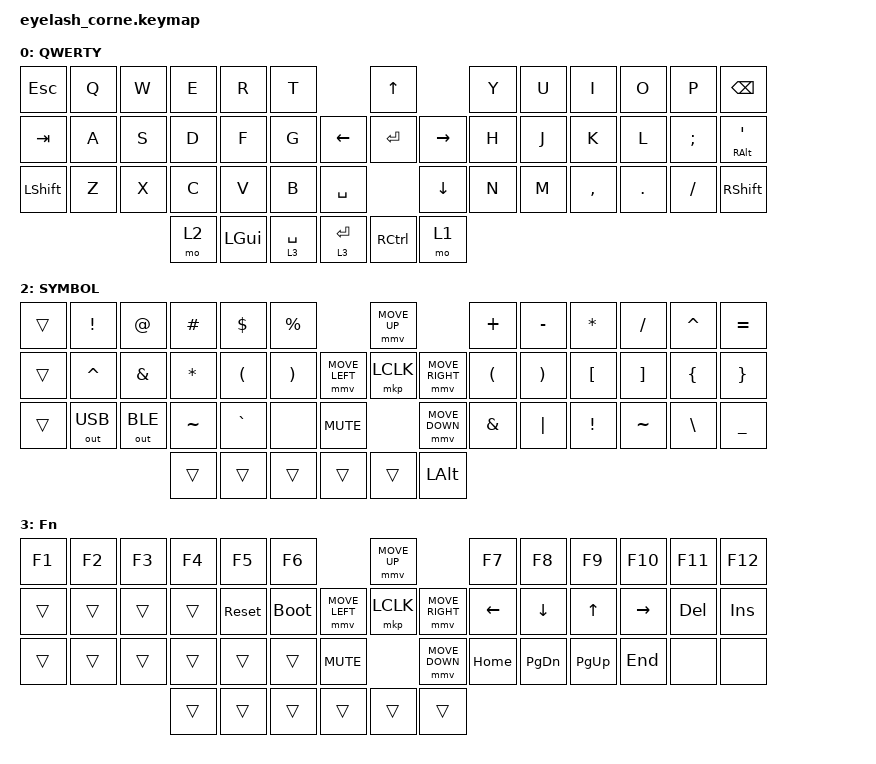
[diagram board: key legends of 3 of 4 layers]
#define ZMK_POINTING_DEFAULT_MOVE_VAL 1200  // 600
#define ZMK_POINTING_DEFAULT_SCRL_VAL 25   // 10

#include <input/processors.dtsi>
#include <zephyr/dt-bindings/input/input-event-codes.h>
#include <behaviors.dtsi>
#include <dt-bindings/zmk/bt.h>
#include <dt-bindings/zmk/ext_power.h>
#include <dt-bindings/zmk/keys.h>
#include <dt-bindings/zmk/outputs.h>
#include <dt-bindings/zmk/pointing.h>
#include <dt-bindings/zmk/rgb.h>

&mmv_input_listener { input-processors = <&zip_xy_scaler 2 1>; };

&msc_input_listener { input-processors = <&zip_scroll_scaler 2 1>; };

&msc {
    acceleration-exponent = <1>;      // 0
    time-to-max-speed-ms = <100>;       // 300
    delay-ms = <0>;                   // 0
};

&mmv {
    time-to-max-speed-ms = <500>;
    acceleration-exponent = <1>;
    trigger-period-ms = <16>;
};

/ {
    behaviors {
        td0: td0 {
            compatible = "zmk,behavior-tap-dance";
            display-name = "Shift/Caps Lock Tap Dance";
            #binding-cells = <0>;
            bindings = <&kp LEFT_SHIFT>, <&kp CAPS>;
        };
    };

    rgb_encoder: rgb_encoder {
        compatible = "zmk,behavior-sensor-rotate";
        #sensor-binding-cells = <0>;
        bindings = <&rgb_ug RGB_BRI>, <&rgb_ug RGB_BRD>;
    };

    scroll_encoder: scroll_encoder {
        compatible = "zmk,behavior-sensor-rotate";
        #sensor-binding-cells = <0>;
        bindings = <&msc SCRL_DOWN>, <&msc SCRL_UP>;
        tap-ms = <100>;
    };

    keymap {
        compatible = "zmk,keymap";

        default_layer {
            display-name = "QWERTY";

            // --------------------------------------------------------------------------------
            // | ESC |  Q  |  W  |  E  |  R  |  T  |   |  Y  |  U  |  I  |  O  |  P  | BKSP |
            // | TAB |  A  |  S  |  D  |  F  |  G  |   |  H  |  J  |  K  |  L  |  ;  |'/ALT | 
            // | SHFT|  Z  |  X  |  C  |  V  |  B  |   |  N  |  M  |  ,  |  .  |  /  | SHFT |
            //                   | SYM | CMD | SPC |   | ENT | CTRL| NUM |

            bindings = <
&kp ESC    &kp Q  &kp W  &kp E   &kp R     &kp T                     &kp UP                 &kp Y        &kp U      &kp I      &kp O    &kp P     &kp BSPC
&kp TAB    &kp A  &kp S  &kp D   &kp F     &kp G        &kp LEFT    &kp ENTER  &kp RIGHT    &kp H        &kp J      &kp K      &kp L    &kp SEMI  &mt RALT SQT
&kp LSHFT  &kp Z  &kp X  &kp C   &kp V     &kp B    &kp SPACE        &kp DOWN               &kp N        &kp M      &kp COMMA  &kp DOT  &kp FSLH  &kp RSHFT
                         &mo 2  &kp LGUI  &lt 3 SPACE     &lt 3 ENTER  &kp RCTRL  &mo 1  
            >;
            sensor-bindings = <&inc_dec_kp C_VOLUME_UP C_VOLUME_DOWN>;
        };

        lower_layer {
            display-name = "NUMBER";

            // -----------------------------------------------------------------------------------------
            // | ESC  |  1  |  2  |  3  |  4  |  5  |    | BT1 | BT2 | BT3 | BT4 |BT_CLR| BKSP |
            // | TAB  |  6  |  7  |  8  |  9  |  0  |    | LFT | DWN | UP  | RGT | HOME | PGUP |
            // | SHFT |L_OFF|L_ON |     |     |     |    | INS | DEL |     |     | END  | PGDN |
            //                    | SYM | CMD | SPC |    | ENT | CTRL| NUM |

            bindings = <
&trans   &kp N1           &kp N2          &kp N3    &kp N4    &kp N5               &mmv MOVE_UP     &bt BT_SEL 0       &bt BT_SEL 1  &bt BT_SEL 2   &bt BT_SEL 3   &bt BT_CLR_ALL  &kp BSPC
&trans   &kp N6           &kp N7          &kp N8    &kp N9    &kp N0   &mmv MOVE_LEFT  &mkp LCLK      &mmv MOVE_RIGHT  &kp LEFT    &kp LEFT       &kp DOWN      &kp UP         &kp RIGHT      &kp HOME        &kp PG_UP     
&trans   &rgb_ug RGB_OFF  &rgb_ug RGB_ON  &none     &none     &none    &kp C_MUTE      &mmv MOVE_DOWN                  &kp INS        &kp DEL       &none          &none          &kp END         &kp PG_DN
                          &trans          &trans    &trans    &trans        &trans         &trans
            >;
            sensor-bindings = <&scroll_encoder>;
        };
//&ext_power EP_OFF  &ext_power EP_ON  &rgb_ug RGB_EFF    &rgb_ug RGB_EFR  &rgb_ug RGB_SPI  &rgb_ug RGB_BRI  &rgb_ug RGB_BRD  
        raise_layer {
            display-name = "SYMBOL";

            // -----------------------------------------------------------------------------------------
            // | ESC |  !  |  @  |  #  |  $  |  %  |   |  +  |  -  |  *  |  /  | ^  |  =  |
            // | TAB |  ^  |  &  |  *  |  (  |  )  |   |  (  |  )  |  [  |  ]  | {  |  }  |
            // | SHFT| USB | BLE |  ~  |  `  |     |   |  &  | "|" |  !  |  ~  | \  |  _  |
            //                   | SYM | CMD | SPC |   | ENT | CTRL| NUM |

            bindings = <
&trans  &kp EXCL      &kp AT        &kp HASH   &kp DLLR  &kp PRCNT               &mmv MOVE_UP                         &kp PLUS  &kp MINUS  &kp ASTRK  &kp FSLH   &kp CARET  &kp EQUAL
&trans  &kp CARET     &kp AMPS      &kp ASTRK  &kp LPAR  &kp RPAR     &mmv MOVE_LEFT  &mkp LCLK      &mmv MOVE_RIGHT  &kp LPAR  &kp RPAR   &kp LBKT   &kp RBKT   &kp LBRC   &kp RBRC
&trans  &out OUT_USB  &out OUT_BLE  &kp TILDE  &kp GRAVE   &none     &kp C_MUTE      &mmv MOVE_DOWN                   &kp AMPS  &kp PIPE   &kp EXCL   &kp TILDE  &kp BSLH   &kp UNDER
                                    &trans     &trans    &trans       &trans    &trans     &kp LALT
            >;
            sensor-bindings = <&scroll_encoder>;
        };

        layer_3 {
            display-name = "Fn";

            // -----------------------------------------------------------------------------------------
            // | F1  | F2 | F3 | F4 | F5 | F6 |   | F7  | F8  | F9  | F10 | F11  | F12  |
            // | TAB |    |    |    |    |    |   | LFT | DWN | UP  | RGT | DEL  | INS  |
            // | SHFT|    |    |    |    |    |   | HOME| PGDN| PGUP| END |      |      |
            //                 |SYM |CMD |SPC |   | ENT | CTRL| NUM |

        bindings = <
&kp F1  &kp F2  &kp F3  &kp F4  &kp F5      &kp F6                 &mmv MOVE_UP      &kp F7    &kp F8     &kp F9  &kp F10      &kp F11  &kp F12
&trans  &trans  &trans  &trans  &sys_reset  &bootloader      &mmv MOVE_LEFT  &mkp LCLK      &mmv MOVE_RIGHT    &kp LEFT  &kp DOWN   &kp UP  &kp RIGHT    &kp DEL  &kp INS  
&trans  &trans  &trans  &trans  &trans      &trans      &kp C_MUTE      &mmv MOVE_DOWN                    &kp HOME  &kp PG_DN  &kp PG_UP   &kp END  &none    &none
                        &trans  &trans      &trans         &trans    &trans     &trans
            >;
            sensor-bindings = <&scroll_encoder>;
        };
    };
};
